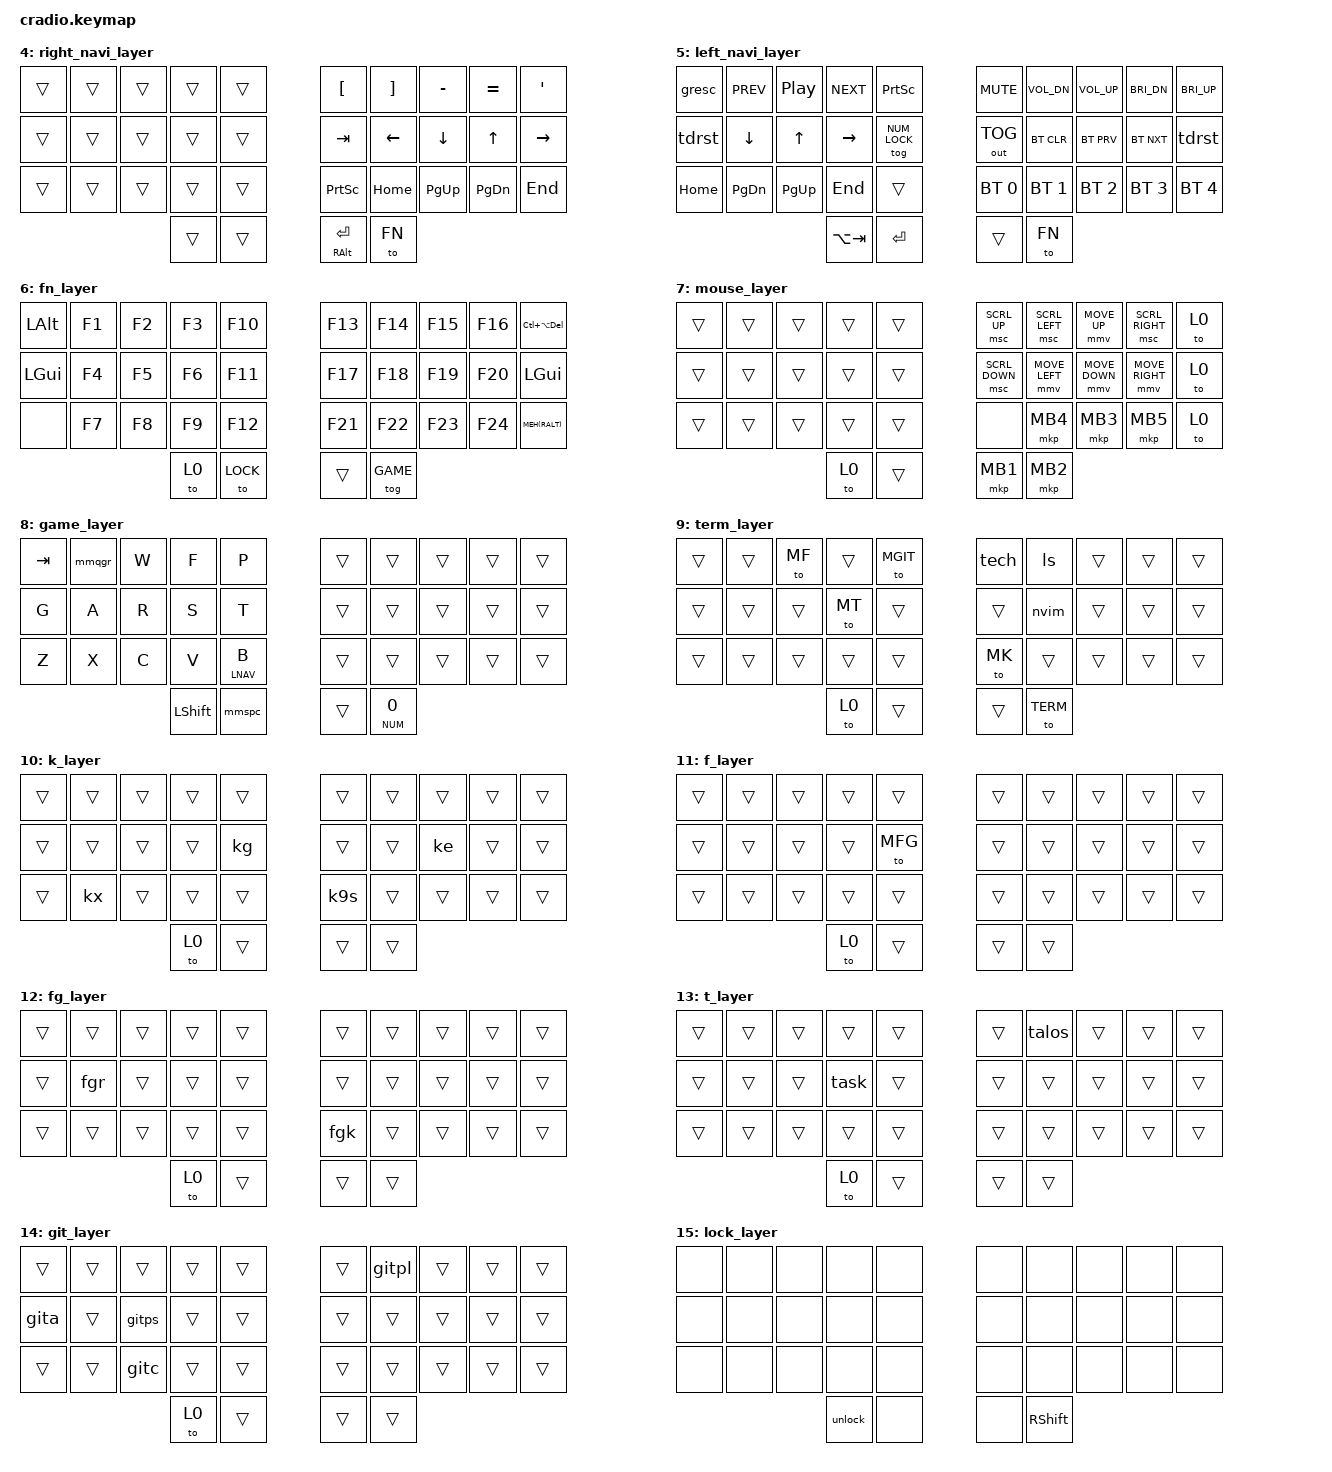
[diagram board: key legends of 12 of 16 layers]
// vi: ft=c
// Copyright (c) 2022 The ZMK Contributors
// SPDX-License-Identifier: MIT

#include <behaviors.dtsi>
// https://github.com/zmkfirmware/zmk/tree/main/app/dts/behaviors
#include <dt-bindings/zmk/keys.h>
#include <dt-bindings/zmk/bt.h>
#include <dt-bindings/zmk/outputs.h>
#include <dt-bindings/zmk/ext_power.h>

// my own code
#include "custom.h"

// timeouts
// current switch timings: stock Akko Crystal Silver on Sweep High
#define CFAST <30>
#define CSLOW <50>

// Layers name to integer definition
#define DEFAULT 0
#define LNUM 1
#define NUM 2
#define NUM_LOCK 3
#define RNAV 4
#define LNAV 5
#define FN 6
#define MOUSE 7
#define GAME 8
#define TERM 9
// macro layers
#define MK 10
#define MF 11
#define MFG 12
#define MT 13
#define MGIT 14
#define LOCK 15

#define EMPTYLAYER \
    &trans  &trans  &trans  &trans  &trans    &trans  &trans  &trans  &trans  &trans \
    &trans  &trans  &trans  &trans  &trans    &trans  &trans  &trans  &trans  &trans \
    &trans  &trans  &trans  &trans  &trans    &trans  &trans  &trans  &trans  &trans \
                            &trans  &trans    &trans  &trans

&sk {
    quick-release;
};
&lt {
    tapping-term-ms = <280>;
    quick-tap-ms = <175>;
    require-prior-idle-ms = <150>;
};
&caps_word {
    continue-list = <BSPC DEL UNDERSCORE MINUS SEMICOLON COLON APOSTROPHE DOUBLE_QUOTES>;
};
// &num_word { // urob fork only
//     layers = <NUM_LOCK>;
//     continue-list = <BSPC DEL DOT AMPERSAND UP DOWN LEFT RIGHT>;
// };

// mouse keys (copied from urob)
#define ZMK_MOUSE_DEFAULT_MOVE_VAL 3750  // 600
#define ZMK_MOUSE_DEFAULT_SCRL_VAL 20    // 10

#include <dt-bindings/zmk/mouse.h>
#include <behaviors/mouse_keys.dtsi>

#include <dt-bindings/zmk/pointing.h>

&mmv {
  acceleration-exponent = <1>;      // 1
  time-to-max-speed-ms = <150>;    // 40
  delay-ms = <0>;                   // 0
};

&msc {
  acceleration-exponent = <2>;      // 0
  time-to-max-speed-ms = <10>;      // 500
  delay-ms = <0>;                   // 10
};

/ {
    behaviors {
        JJ_MM(unlock, unlock, mods = <(MOD_RSFT)>; bindings = <&none>, <&unlockdance>;)
        JJ(unlockdance, unlock_dance, "zmk,behavior-tap-dance", 0, tapping-term-ms = <200>; bindings = <&none>, <&none>, <&to 0>;)
        JJ_TD(tdc, tap_dance_colon, <&kp COLON>, <&kp APOSTROPHE>, <&kp DOUBLE_QUOTES>, <&kp SEMICOLON>)
        JJ_MM(mmsc, mod_morph_semicolon, mods = <(MOD_LSFT)>; bindings = <&tdc>, <&kp SEMICOLON>;)
        JJ_MM(mmsa, mod_morph_semicolon_apostrophe, mods = <(MOD_RALT)>; bindings = <&mmsc>, <&kp DOUBLE_QUOTES>;)
        JJ_MM(mmoe, mod_morph_o_enter, mods = <(MOD_RALT)>; bindings = <&kp O>, <&kp ENTER>;)
        JJ_MM(mmgrave, mod_morph_grave, mods = <(MOD_LSFT)>; bindings = <&kp TILDE>, <&kp GRAVE>;)
        JJ_MM(mmpipe, mod_morph_pipe_backslash, mods = <(MOD_LSFT)>; bindings = <&kp PIPE>, <&kp BSLH>;)
        JJ_MM(mmqgr, mod_morph_q_grave, mods = <(MOD_RALT)>; bindings = <&kp Q>, <&mmgrave>;)
        JJ_MM(mmat, mod_morph_a_tab, mods = <(MOD_RALT|MOD_RGUI)>; keep-mods = <(MOD_RALT|MOD_RGUI)>; bindings = <&kp A>, <&kp TAB>;)
        JJ_MM(mmrr, mod_morph_r_repeat_key, mods = <(MOD_RALT)>; bindings = <&kp R>, <&key_repeat>;)
        JJ_MM(mmts, mod_morph_t_shift, mods = <(MOD_RALT|MOD_LALT)>; bindings = <&kp T>, <&sk LSHFT>;)
        JJ_MM(mmns, mod_morph_n_shift, mods = <(MOD_RALT|MOD_LALT)>; bindings = <&kp N>, <&sk LSHFT>;)
        JJ_MM(mmcaps, mod_morph_caps, mods = <(MOD_LSFT)>; bindings = <&kp ESC>, <&kp CAPSLOCK>;)
        JJ_MM(mmspc, mod_morph_space_caps_word, mods = <(MOD_LSFT)>; bindings = <&kp SPACE>, <&caps_word>;)
        JJ_HT_HOLD(caps, caps_word_hold, bindings = <&kp>, <&mmcaps>;)
        JJ_HT_HOLD(spc, space_stuff, bindings = <&kp>, <&mmspc>;)
        // JJ_HT_HOLD(shft, smart_shift, hold-while-undecided; bindings = <&kp>, <&mmshift>;)
        // JJ_MM(mmshift, mod_morph_shift, mods = <(MOD_LSFT)>; bindings = <&sk LSHFT>, <&caps_word>;)
        // JJ_HT_HOLD(spc, space_shift, bindings = <&kp>, <&kp>;)
        JJ_HT_HOLD(rm, repeat_mod, bindings = <&kp>, <&key_repeat>;)
        JJ_HT_HOLD(mto, mod_tap_to_layer, bindings = <&sk>, <&to>;)
        JJ_HT_HOLD(mtog, mod_tap_toggle_layer, bindings = <&sk>, <&tog>;)
        JJ_HT_HOLD(lt2, layer_tap_2, bindings = <&mo>, <&to>;)
        JJ_MM(mmzd, mod_morph_z_delete, mods = <(MOD_RALT)>; bindings = <&kp Z>, <&kp DEL>;)
        JJ_HT_TAP(ltz, layer_tap_z, bindings = <&mo>, <&mmzd>;)
        JJ_HT_TAP(hm, homerow_mods, bindings = <&kp>, <&kp>;)
        JJ_HML_34(hl, homerow_mods_left, bindings = <&kp>, <&kp>;)
        JJ_HMR_34(hr, homerow_mods_right, bindings = <&kp>, <&kp>;)
        JJ_HT_HOLD(nl, num_layer_stuff, quick-tap-ms = <200>; bindings = <&mo>, <&key_repeat>;)
        // JJ_HT_HOLD(nl, num_layer_stuff, hold-while-undecided; bindings = <&mo>, <&mmnl>;)
        JJ_HT_HOLD(bs, backspace_meh, quick-tap-ms = <200>; bindings = <&kp>, <&kp>;)
        // JJ_MM(mmnl, mod_morph_num_layer_caps_word, mods = <(MOD_LSFT)>; bindings = <&key_repeat>, <&kp CAPSLOCK>;)
        JJ_TD(numdot, num_layer_dot, <&kp DOT>, <&none>, <&kp LC(LA(DEL))>, <&tog GAME>)
        JJ_MM(mmctrlspc, mod_morph_ctrl_space, mods = <(MOD_LSFT)>; bindings = <&kp SPACE>, <&kp LCTRL>;)
        JJ_TD(tdrst, tap_dance_reset, <&sys_reset>, <&none>, <&bootloader>)
    };
    keymap {
        compatible = "zmk,keymap";
        default_layer {
            bindings = <
            //╭──────────┬──────────┬──────────┬──────────┬──────────╮   ╭──────────┬──────────┬──────────┬──────────┬──────────╮
            //│  Q       │  W       │  F       │  P       │  G       │   │  J       │  L       │  U       │  Y       │ :;"'     │
                &mmqgr     &kp W      &kp F      &kp P      &kp G          &kp J      &kp L      &kp U      &kp Y      &mmsa
            //├──────────┼──────────┼──────────┼──────────┼──────────┤   ├──────────┼──────────┼──────────┼──────────┼──────────┤
            //│  A       │  R       │  S       │  T       │  D       │   │  H       │  N       │  E       │  I       │  O       │
                &mmat      &mmrr      &kp S      &mmts     &lt TERM D      &kp H      &mmns      &kp E      &kp I      &kp O
            //├──────────┼──────────┼──────────┼──────────┼──────────┤   ├──────────┼──────────┼──────────┼──────────┼──────────┤
            //│  Z       │  X       │  C       │  V       │  B       │   │  K       │  M       │  ,<      │  .>      │  /?      │
               &ltz FN Z &hl LCTRL X &hl RALT C &hl RGUI V &lt LNAV B     &kp K &hr LGUI M &hr LALT COMMA &hr LCTRL DOT &lt MOUSE FSLH
            //╰──────────┴──────────┴──────────┼──────────┼──────────┤   ├──────────┼──────────┼──────────┴──────────┴──────────╯
                                    &caps LCTRL ESC &spc LSHFT SPACE &bs MEH(RALT) BSPC &nl NUM NUM
            //                                 ╰──────────┴──────────╯   ╰──────────┴──────────╯
            // esc gets thumb cuz vim & as safe key to verify layer 0
	    // mmsa = tap for colon, shift for semicolon, RALT for double quotes, NUM layer for single quotes
            >;
        };
        num_layer {
            bindings = < // TODO: decide whether to split this or not
            //╭──────────┬──────────┬──────────┬──────────┬──────────╮   ╭──────────┬──────────┬──────────┬──────────┬──────────╮
            //│ `~       │  1       │  2       │  3       │  \|      │   │ [{       │ HOME     │ UP       │ END      │ =+       │
                &mmgrave   &kp N1     &kp N2     &kp N3     &kp COMMA      &mmpipe &hm PG_UP HOME &kp UP &hm PG_DN END &kp BSPC
            //├──────────┼──────────┼──────────┼──────────┼──────────┤   ├──────────┼──────────┼──────────┼──────────┼──────────┤
            //│ TAB      │  4       │  5       │  6       │  .       │   │ ]}       │ LEFT     │ DOWN     │ RIGHT    │ '"       │
                &kp ESC    &kp N4     &kp N5     &kp N6     &kp DOT        &kp TAB    &kp LEFT   &kp DOWN   &kp RIGHT  &kp APOS
            //├──────────┼──────────┼──────────┼──────────┼──────────┤   ├──────────┼──────────┼──────────┼──────────┼──────────┤
            //│ DELETE   │  7       │  8       │  9       │  0       │   │ TAB      │ PG_UP    │ -_       │ PG_DN    │ PSCRN    │
                &kp DEL    &kp N7     &kp N8     &kp N9     &kp N0         &kp LBKT   &kp RBKT   &kp MINUS  &kp EQUAL  &kp PSCRN
            //╰──────────┴──────────┴──────────┼──────────┼──────────┤   ├──────────┼──────────┼──────────┴──────────┴──────────╯
                                    &mtog LCTRL NUM_LOCK &spc LSHFT SPACE &bs MEH(RALT) BSPC &none
            //                                 ╰──────────┴──────────╯   ╰──────────┴──────────╯
            >;
        };
        num_hold_layer { bindings = <EMPTYLAYER>; };
        num_lock_layer { bindings = <EMPTYLAYER>; };
        right_navi_layer {
            bindings = <
            //╭──────────┬──────────┬──────────┬──────────┬──────────╮   ╭──────────┬──────────┬──────────┬──────────┬──────────╮
            //│ `~       │  1       │  2       │  3       │  \|      │   │ [{       │ ]}       │ -_       │ =+       │ '"       │
                &trans     &trans     &trans     &trans     &trans         &kp LBKT   &kp RBKT   &kp MINUS  &kp EQUAL  &kp APOS
            //├──────────┼──────────┼──────────┼──────────┼──────────┤   ├──────────┼──────────┼──────────┼──────────┼──────────┤
            //│ TAB      │  4       │  5       │  6       │  0       │   │ TAB      │ LEFT     │ DOWN     │ UP       │ RIGHT    │
                &trans     &trans     &trans     &trans     &trans         &kp TAB    &kp LEFT   &kp DOWN   &kp UP     &kp RIGHT
            //├──────────┼──────────┼──────────┼──────────┼──────────┤   ├──────────┼──────────┼──────────┼──────────┼──────────┤
            //│ DELETE   │  7       │  8       │  9       │  0       │   │ PSCRN    │ HOME     │ PG_UP    │ PG_DN    │ END      │
                &trans     &trans     &trans     &trans     &trans         &kp PSCRN  &kp HOME   &kp PG_UP &kp PG_DN   &kp END
            //╰──────────┴──────────┴──────────┼──────────┼──────────┤   ├──────────┼──────────┼──────────┴──────────┴──────────╯
                                                &trans      &trans        &mt RALT ENTER &to FN
            //                                 ╰──────────┴──────────╯   ╰──────────┴──────────╯
            >;
        };
        left_navi_layer {
            bindings = <
            //╭──────────┬──────────┬──────────┬──────────┬──────────╮   ╭──────────┬──────────┬──────────┬──────────┬──────────╮
            //│ `~ESC    │ PREV SONG│PLAY/PAUSE│ NEXT SONG│ PSCRN    │   │          │          │          │          │          │
                &gresc    &kp C_PREV  &kp C_PP  &kp C_NEXT  &kp PSCRN &kp C_MUTE &kp C_VOL_DN &kp C_VOL_UP &kp C_BRI_DN &kp C_BRI_UP
            //├──────────┼──────────┼──────────┼──────────┼──────────┤   ├──────────┼──────────┼──────────┼──────────┼──────────┤
            //│ LEFT     │ DOWN     │ UP       │ RIGHT    │ Num Layer│   │          │TODO:BTDSC│          │          │          │
                &tdrst   &kp DOWN   &kp UP   &kp RIGHT &tog NUM_LOCK      &out OUT_TOG &bt BT_CLR &bt BT_PRV &bt BT_NXT &tdrst
            //├──────────┼──────────┼──────────┼──────────┼──────────┤   ├──────────┼──────────┼──────────┼──────────┼──────────┤
            //│ HOME     │ PG_DN    │ PG_UP    │ END      │          │   │          │          │          │          │          │
                &kp HOME  &kp PG_DN   &kp PG_UP  &kp END    &trans    &bt BT_SEL 0 &bt BT_SEL 1 &bt BT_SEL 2 &bt BT_SEL 3 &bt BT_SEL 4
            //╰──────────┴──────────┴──────────┼──────────┼──────────┤   ├──────────┼──────────┼──────────┴──────────┴──────────╯
                                                &kp LA(TAB) &kp ENTER      &trans     &to FN
            //                                 ╰──────────┴──────────╯   ╰──────────┴──────────╯
            >;
        };
        fn_layer {
            bindings = <
            //╭──────────┬──────────┬──────────┬──────────┬──────────╮   ╭──────────┬──────────┬──────────┬──────────┬──────────╮
            //│ LALT     │ F1       │ F2       │ F3       │ F10      │   │ F13      │ F14      │ F15      │ F16      │ LALT     │
                &kp LALT   &kp F1     &kp F2     &kp F3     &kp F10        &kp F13    &kp F14    &kp F15    &kp F16 &kp LC(LA(DEL))
            //├──────────┼──────────┼──────────┼──────────┼──────────┤   ├──────────┼──────────┼──────────┼──────────┼──────────┤
            //│ LGUI     │ F4       │ F5       │ F6       │ F11      │   │ F18      │ F19      │ F20      │ F21      │ LGUI     │
                &kp LGUI   &kp F4     &kp F5     &kp F6     &kp F11        &kp F17    &kp F18    &kp F19    &kp F20    &kp LGUI
            //├──────────┼──────────┼──────────┼──────────┼──────────┤   ├──────────┼──────────┼──────────┼──────────┼──────────┤
            //│ NONE     │ F7       │ F8       │ F9       │ F12      │   │ F23      │ F24      │ F23      │ F24      │ MEH      │
                &none      &kp F7     &kp F8     &kp F9     &kp F12        &kp F21    &kp F22    &kp F23    &kp F24 &kp MEH(RALT)
            //╰──────────┴──────────┴──────────┼──────────┼──────────┤   ├──────────┼──────────┼──────────┴──────────┴──────────╯
                                                &to 0       &to LOCK       &trans     &tog GAME
            //                                 ╰──────────┴──────────╯   ╰──────────┴──────────╯
            >;
        };
        mouse_layer {
            bindings = <
            //╭──────────┬──────────┬──────────┬──────────┬──────────╮   ╭──────────┬──────────┬──────────┬──────────┬──────────╮
            //│ `~       │  1       │  2       │  3       │  \|      │   │ [{       │ ]}       │ -_       │ =+       │ '"       │
                &trans     &trans     &trans     &trans     &trans &msc SCRL_UP &msc SCRL_LEFT &mmv MOVE_UP &msc SCRL_RIGHT &to 0
            //├──────────┼──────────┼──────────┼──────────┼──────────┤   ├──────────┼──────────┼──────────┼──────────┼──────────┤
            //│ TAB      │  4       │  5       │  6       │  0       │   │ TAB      │ LEFT     │ DOWN     │ UP       │ RIGHT    │
                &trans     &trans     &trans     &trans     &trans &msc SCRL_DOWN &mmv MOVE_LEFT &mmv MOVE_DOWN &mmv MOVE_RIGHT &to 0
            //├──────────┼──────────┼──────────┼──────────┼──────────┤   ├──────────┼──────────┼──────────┼──────────┼──────────┤
            //│ DELETE   │  7       │  8       │  9       │  0       │   │ PSCRN    │ HOME     │ PG_UP    │ PG_DN    │ END      │
                &trans     &trans     &trans     &trans     &trans         &none      &mkp MB4   &mkp MB3   &mkp MB5   &to 0
            //╰──────────┴──────────┴──────────┼──────────┼──────────┤   ├──────────┼──────────┼──────────┴──────────┴──────────╯
                                                &to 0       &trans         &mkp MB1   &mkp MB2
            //                                 ╰──────────┴──────────╯   ╰──────────┴──────────╯
            >;
        };
        game_layer {
            bindings = <
            // NOTE: This is suited to my gaming habits.
            // I don't ever bind anything to D (QWERTY's G) so that I don't accidentally fat finger T (QWERTY's F) and throw a grenade.
            // I want the row stagger of the middle 3 rows for WASD as the leftmost 3 rows is awkward, 
            // and I want pinky to be used for things other than sprint, thus the shift of the first 2 rows by 1 column to the right.
            //╭──────────┬──────────┬──────────┬──────────┬──────────╮   ╭──────────┬──────────┬──────────┬──────────┬──────────╮
            //│  TAB     │  Q       │  W       │  F       │  P       │   │  J       │  L       │  U       │  Y       │ ;:'"     │
                &kp TAB    &mmqgr     &kp W      &kp F      &kp P          &trans     &trans     &trans     &trans     &trans
            //├──────────┼──────────┼──────────┼──────────┼──────────┤   ├──────────┼──────────┼──────────┼──────────┼──────────┤
            //│  G       │  A       │  R       │  S       │  T       │   │  H       │  N       │  E       │  I       │  O       │
                &kp G      &kp A      &kp R      &kp S      &kp T          &trans     &trans     &trans     &trans     &trans
            //├──────────┼──────────┼──────────┼──────────┼──────────┤   ├──────────┼──────────┼──────────┼──────────┼──────────┤
            //│  Z       │  X       │  C       │  V       │  B       │   │  K       │  M       │  ,<      │  .>      │  /?      │
                &kp Z      &kp X      &kp C      &kp V     &lt LNAV B      &trans     &trans     &trans     &trans     &trans
            //╰──────────┴──────────┴──────────┼──────────┼──────────┤   ├──────────┼──────────┼──────────┴──────────┴──────────╯
                                                &kp LSHFT   &mmspc         &trans    &lt2 NUM 0
            //                                 ╰──────────┴──────────╯   ╰──────────┴──────────╯
            // esc gets thumb cuz vim & as safe key to verify layer 0
            >;
        };
        term_layer {
            bindings = <
            //╭──────────┬──────────┬──────────┬──────────┬──────────╮   ╭──────────┬──────────┬──────────┬──────────┬──────────╮
            //│  Q       │  W       │  F       │  P       │  G       │   │  J       │  L       │  U       │  Y       │ ;:'"     │
                &trans     &trans     &to MF     &trans     &to MGIT       &tech      &ls        &trans     &trans     &trans
            //├──────────┼──────────┼──────────┼──────────┼──────────┤   ├──────────┼──────────┼──────────┼──────────┼──────────┤
            //│  A       │  R       │  S       │  T       │  D       │   │  H       │  N       │  E       │  I       │  O       │
                &trans     &trans     &trans     &to MT     &trans         &trans     &nvim      &trans     &trans     &trans
            //├──────────┼──────────┼──────────┼──────────┼──────────┤   ├──────────┼──────────┼──────────┼──────────┼──────────┤
            //│  Z       │  X       │  C       │  V       │  B       │   │  K       │  M       │  ,<      │  .>      │  /?      │
                &trans     &trans     &trans     &trans     &trans         &to MK     &trans     &trans     &trans     &trans
            //╰──────────┴──────────┴──────────┼──────────┼──────────┤   ├──────────┼──────────┼──────────┴──────────┴──────────╯
                                                &to 0       &trans         &trans     &to TERM
            //                                 ╰──────────┴──────────╯   ╰──────────┴──────────╯
            >;
        };
        k_layer {
            bindings = <
            //╭──────────┬──────────┬──────────┬──────────┬──────────╮   ╭──────────┬──────────┬──────────┬──────────┬──────────╮
            //│  Q       │  W       │  F       │  P       │  B       │   │  J       │  L       │  U       │  Y       │ '"       │
                &trans     &trans     &trans     &trans     &trans         &trans     &trans     &trans     &trans     &trans
            //├──────────┼──────────┼──────────┼──────────┼──────────┤   ├──────────┼──────────┼──────────┼──────────┼──────────┤
            //│  A       │  R       │  S       │  T       │  G       │   │  M       │  N       │  E       │  I       │  O       │
                &trans     &trans     &trans     &trans     &kg            &trans     &trans     &ke        &trans     &trans
            //├──────────┼──────────┼──────────┼──────────┼──────────┤   ├──────────┼──────────┼──────────┼──────────┼──────────┤
            //│  Z       │  X       │  C       │  D       │  V       │   │  K       │  H       │  ,<      │  .>      │  /?      │
                &trans     &kx        &trans     &trans     &trans         &k9s       &trans     &trans     &trans     &trans
            //╰──────────┴──────────┴──────────┼──────────┼──────────┤   ├──────────┼──────────┼──────────┴──────────┴──────────╯
                                                &to 0       &trans         &trans     &trans
            //                                 ╰──────────┴──────────╯   ╰──────────┴──────────╯
            >;
        };
        f_layer {
            bindings = <
            //╭──────────┬──────────┬──────────┬──────────┬──────────╮   ╭──────────┬──────────┬──────────┬──────────┬──────────╮
            //│  Q       │  W       │  F       │  P       │  B       │   │  J       │  L       │  U       │  Y       │ '"       │
                &trans     &trans     &trans     &trans     &trans         &trans     &trans     &trans     &trans     &trans
            //├──────────┼──────────┼──────────┼──────────┼──────────┤   ├──────────┼──────────┼──────────┼──────────┼──────────┤
            //│  A       │  R       │  S       │  T       │  G       │   │  M       │  N       │  E       │  I       │  O       │
                &trans     &trans     &trans     &trans     &to MFG        &trans     &trans     &trans     &trans     &trans
            //├──────────┼──────────┼──────────┼──────────┼──────────┤   ├──────────┼──────────┼──────────┼──────────┼──────────┤
            //│  Z       │  X       │  C       │  D       │  V       │   │  K       │  H       │  ,<      │  .>      │  /?      │
                &trans     &trans     &trans     &trans     &trans         &trans     &trans     &trans     &trans     &trans
            //╰──────────┴──────────┴──────────┼──────────┼──────────┤   ├──────────┼──────────┼──────────┴──────────┴──────────╯
                                                &to 0       &trans         &trans     &trans
            //                                 ╰──────────┴──────────╯   ╰──────────┴──────────╯
            >;
        };
        fg_layer {
            bindings = <
            //╭──────────┬──────────┬──────────┬──────────┬──────────╮   ╭──────────┬──────────┬──────────┬──────────┬──────────╮
            //│  Q       │  W       │  F       │  P       │  B       │   │  J       │  L       │  U       │  Y       │ '"       │
                &trans     &trans     &trans     &trans     &trans         &trans     &trans     &trans     &trans     &trans
            //├──────────┼──────────┼──────────┼──────────┼──────────┤   ├──────────┼──────────┼──────────┼──────────┼──────────┤
            //│  A       │  R       │  S       │  T       │  G       │   │  M       │  N       │  E       │  I       │  O       │
                &trans     &fgr       &trans     &trans     &trans         &trans     &trans     &trans     &trans     &trans
            //├──────────┼──────────┼──────────┼──────────┼──────────┤   ├──────────┼──────────┼──────────┼──────────┼──────────┤
            //│  Z       │  X       │  C       │  D       │  V       │   │  K       │  H       │  ,<      │  .>      │  /?      │
                &trans     &trans     &trans     &trans     &trans         &fgk       &trans     &trans     &trans     &trans
            //╰──────────┴──────────┴──────────┼──────────┼──────────┤   ├──────────┼──────────┼──────────┴──────────┴──────────╯
                                                &to 0       &trans         &trans     &trans
            //                                 ╰──────────┴──────────╯   ╰──────────┴──────────╯
            >;
        };
        t_layer {
            bindings = <
            //╭──────────┬──────────┬──────────┬──────────┬──────────╮   ╭──────────┬──────────┬──────────┬──────────┬──────────╮
            //│  Q       │  W       │  F       │  P       │  B       │   │  J       │  L       │  U       │  Y       │ '"       │
                &trans     &trans     &trans     &trans     &trans         &trans     &talos     &trans     &trans     &trans
            //├──────────┼──────────┼──────────┼──────────┼──────────┤   ├──────────┼──────────┼──────────┼──────────┼──────────┤
            //│  A       │  R       │  S       │  T       │  G       │   │  M       │  N       │  E       │  I       │  O       │
                &trans     &trans     &trans     &task      &trans         &trans     &trans     &trans     &trans     &trans
            //├──────────┼──────────┼──────────┼──────────┼──────────┤   ├──────────┼──────────┼──────────┼──────────┼──────────┤
            //│  Z       │  X       │  C       │  D       │  V       │   │  K       │  H       │  ,<      │  .>      │  /?      │
                &trans     &trans     &trans     &trans     &trans         &trans     &trans     &trans     &trans     &trans
            //╰──────────┴──────────┴──────────┼──────────┼──────────┤   ├──────────┼──────────┼──────────┴──────────┴──────────╯
                                                &to 0       &trans         &trans     &trans
            //                                 ╰──────────┴──────────╯   ╰──────────┴──────────╯
            >;
        };
        git_layer {
            bindings = <
            //╭──────────┬──────────┬──────────┬──────────┬──────────╮   ╭──────────┬──────────┬──────────┬──────────┬──────────╮
            //│  Q       │  W       │  F       │  P       │  G       │   │  J       │  L       │  U       │  Y       │ ;:'"     │
                &trans     &trans     &trans     &trans     &trans         &trans     &gitpl     &trans     &trans     &trans
            //├──────────┼──────────┼──────────┼──────────┼──────────┤   ├──────────┼──────────┼──────────┼──────────┼──────────┤
            //│  A       │  R       │  S       │  T       │  D       │   │  H       │  N       │  E       │  I       │  O       │
                &gita      &trans     &gitps     &trans     &trans         &trans     &trans     &trans     &trans     &trans
            //├──────────┼──────────┼──────────┼──────────┼──────────┤   ├──────────┼──────────┼──────────┼──────────┼──────────┤
            //│  Z       │  X       │  C       │  V       │  B       │   │  K       │  M       │  ,<      │  .>      │  /?      │
                &trans     &trans     &gitc      &trans     &trans         &trans     &trans     &trans     &trans     &trans
            //╰──────────┴──────────┴──────────┼──────────┼──────────┤   ├──────────┼──────────┼──────────┴──────────┴──────────╯
                                                &to 0       &trans         &trans     &trans
            //                                 ╰──────────┴──────────╯   ╰──────────┴──────────╯
            >;
        };
        lock_layer {
            bindings = <
                &none &none &none &none &none  &none &none &none &none &none
                &none &none &none &none &none  &none &none &none &none &none
                &none &none &none &none &none  &none &none &none &none &none
                                &unlock &none  &none &kp RSHFT
            >;
        };
	// TODO: mouse layer
    };
    macros {
        ZMK_MACRO(smart_shift, bindings = <&macro_release &caps_word>, <&sk LSHFT>;)
        ZMK_MACRO(nvim, bindings = <&kp N &kp V &kp I &kp M &kp SPACE &to 0>;)
        ZMK_MACRO(ls, bindings = <&kp L &kp S &kp SPACE &kp KP_MINUS>, <&macro_press &kp LSHFT>, <&kp A>, <&macro_release &kp LSHFT>, <&kp L &kp H &kp SPACE &to 0>;)
        ZMK_MACRO(task, bindings = <&kp T &kp A &kp S &kp K &kp SPACE &to 0>;)
        ZMK_MACRO(talos, bindings = <&kp T &kp A &kp L &kp O &kp S &kp C &kp T &kp L &kp SPACE &to 0>;) // talosctl
        ZMK_MACRO(tech, bindings = <&kp J &kp J &kp G &kp A &kp D &kp G &kp E &kp T &kp S &kp DOT &kp T &kp E &kp C &kp H &to 0>;) // jjgadgets.tech
        ZMK_MACRO(gita, bindings = <&kp G &kp I &kp T &kp SPACE &kp A &kp D &kp D &kp SPACE &to 0>;) // git add
        ZMK_MACRO(gitc, bindings = <&kp G &kp I &kp T &kp SPACE &kp C &kp O &kp M &kp M &kp I &kp T &kp SPACE &kp KP_MINUS &kp KP_MINUS &kp G &kp P &kp G &kp KP_MINUS &kp S &kp I &kp G &kp N &kp SPACE &kp KP_MINUS &kp M &kp SPACE &kp DOUBLE_QUOTES &kp DOUBLE_QUOTES &kp LEFT &kp SPACE &to 0>;) // git add
        ZMK_MACRO(gitps, bindings = <&kp G &kp I &kp T &kp SPACE &kp P &kp U &kp S &kp H &to 0>;)
        ZMK_MACRO(gitpl, bindings = <&kp G &kp I &kp T &kp SPACE &kp P &kp U &kp L &kp L &to 0>;)
        ZMK_MACRO(fgr, bindings = <&kp F &kp L &kp U &kp X &kp SPACE &kp G &kp E &kp T &kp SPACE &kp H &kp R &kp SPACE &kp KP_MINUS &kp N &kp SPACE &to 0>;) // flux get hr
        ZMK_MACRO(fgk, bindings = <&kp F &kp L &kp U &kp X &kp SPACE &kp G &kp E &kp T &kp SPACE &kp K &kp S &kp SPACE &to 0>;) // flux get ks
        ZMK_MACRO(k9s, bindings = <&kp K &kp N9 &kp S &kp ENTER &to 0>;)
        ZMK_MACRO(kg, bindings = <&kp K &kp U &kp B &kp E &kp C &kp T &kp L &kp SPACE &kp G &kp E &kp T &kp SPACE &kp KP_MINUS &kp N &kp SPACE &kp LEFT &kp LEFT &kp LEFT &kp LEFT &kp SPACE &to 0>;) // kubectl get -n
        ZMK_MACRO(ke, bindings = <&kp K &kp U &kp B &kp E &kp C &kp T &kp L &kp SPACE &kp E &kp D &kp I &kp T &kp SPACE &kp KP_MINUS &kp N &kp SPACE &kp LEFT &kp LEFT &kp LEFT &kp LEFT &kp SPACE &to 0>;) // kubectl edit -n
        ZMK_MACRO(kx, bindings = <&kp K &kp U &kp B &kp E &kp C &kp T &kp L &kp SPACE &kp E &kp X &kp E &kp C &kp SPACE &kp KP_MINUS &kp I &kp T &kp SPACE &kp KP_MINUS &kp N &kp SPACE &kp KP_MINUS &kp KP_MINUS &kp SPACE &kp B &kp A &kp S &kp H &kp LEFT &kp LEFT &kp LEFT &kp LEFT &kp LEFT &kp LEFT &kp LEFT &kp LEFT &kp SPACE &to 0>;) // kubectl exec -it -n
    };
    combos {
        compatible = "zmk,combos";
        game_ctrl {
            timeout-ms = CSLOW;
            key-positions = <31 10>; // left outer thumb + A (default) or G (gaming)
            bindings = <&kp LCTRL>;
            layers = <GAME>;
        };
        game_ctrl2 {
            timeout-ms = CSLOW;
            key-positions = <30 10>; // left outer thumb + A (default) or G (gaming)
            bindings = <&kp LCTRL>;
            layers = <GAME>;
        };
        game_d {
            timeout-ms = CSLOW;
            key-positions = <31 14>; // left outer thumb + D (default) or T (gaming)
            bindings = <&kp D>;
            layers = <GAME>;
        };
        game_d2 {
            timeout-ms = CSLOW;
            key-positions = <30 14>; // left outer thumb + D (default) or T (gaming)
            bindings = <&kp D>;
            layers = <GAME>;
        };
        game_space_hold {
            timeout-ms = CSLOW;
            key-positions = <31 32>; // left outer thumb + D (default) or T (gaming)
            bindings = <&kt SPACE>;
            layers = <GAME>;
        };
        game_esc {
            timeout-ms = CFAST;
            key-positions = <0 1>; // Q + W
            bindings = <&kp ESC>;
            layers = <GAME>;
            require-prior-idle-ms = <JJ_COMBO_IDLE>;
        };
        combo_mouse_layer {
            timeout-ms = CSLOW;
            key-positions = <6 7 8>; // L U Y
            bindings = <&tog MOUSE>;
            layers = <0 LNUM MOUSE GAME>;
            require-prior-idle-ms = <JJ_COMBO_IDLE>;
        };
        combo_grave {
            timeout-ms = CFAST;
            key-positions = <0 1>; // Q + W
            bindings = <&mmgrave>;
            layers = <0>;
            require-prior-idle-ms = <JJ_COMBO_IDLE>;
        };
        combo_tab {
            timeout-ms = CSLOW;
            key-positions = <11 12 13>; // R + S + T
            bindings = <&kp TAB>;
            layers = <0 LNUM NUM_LOCK>;
            require-prior-idle-ms = <JJ_COMBO_IDLE>;
        };
        combo_delete {
            timeout-ms = CFAST;
            key-positions = <20 21>; // Z + X
            bindings = <&kp DEL>;
            layers = <0>;
            require-prior-idle-ms = <JJ_COMBO_IDLE>;
        };
        combo_enter {
            timeout-ms = CSLOW;
            key-positions = <16 17 18>; // N + E + I
            bindings = <&kp ENTER>;
            require-prior-idle-ms = <JJ_COMBO_IDLE>;
        };
        combo_double_quotes {
            timeout-ms = CFAST;
            key-positions = <8 9>; // Y + :
            bindings = <&kp DOUBLE_QUOTES>;
            layers = <0>;
            require-prior-idle-ms = <JJ_COMBO_IDLE>;
        };
        combo_semicolon {
            timeout-ms = CFAST;
            key-positions = <9 19>; // O + :
            bindings = <&kp SEMICOLON>;
            layers = <0>;
            require-prior-idle-ms = <JJ_COMBO_IDLE>;
        };
        combo_left {
            timeout-ms = CSLOW;
            key-positions = <33 16>; // right outer thumb + O key
            bindings = <&kp LEFT>;
            layers = <0>;
        };
        combo_down {
            timeout-ms = CSLOW;
            key-positions = <33 17>; // right outer thumb + O key
            bindings = <&kp DOWN>;
            layers = <0>;
        };
        combo_up {
            timeout-ms = CSLOW;
            key-positions = <33 7>; // right outer thumb + O key
            bindings = <&kp UP>;
            layers = <0>;
        };
        combo_right {
            timeout-ms = CSLOW;
            key-positions = <33 18>; // right outer thumb + O key
            bindings = <&kp RIGHT>;
            layers = <0>;
        };
        combo_apos {
            timeout-ms = CSLOW;
            key-positions = <33 19>; // right outer thumb + O key
            bindings = <&kp APOS>;
            layers = <0>;
        };
        combo_hyphen {
            timeout-ms = CSLOW;
            key-positions = <33 27>; // right outer thumb + O key
            bindings = <&kp MINUS>;
            layers = <0>;
        };
        combo_equal {
            timeout-ms = CSLOW;
            key-positions = <33 28>; // right outer thumb + O key
            bindings = <&kp EQUAL>;
            layers = <0>;
        };
        combo_exclamation {
            timeout-ms = CFAST;
            key-positions = <1 2>; // W + F
            bindings = <&kp EXCLAMATION>;
            layers = <0>;
            require-prior-idle-ms = <JJ_COMBO_IDLE>;
        };
        combo_at {
            timeout-ms = CFAST;
            key-positions = <2 3>; // F + P
            bindings = <&kp AT_SIGN>;
            layers = <0>;
            require-prior-idle-ms = <JJ_COMBO_IDLE>;
        };
        combo_hash {
            timeout-ms = CFAST;
            key-positions = <3 4>; // F + P
            bindings = <&kp HASH>;
            layers = <0>;
            require-prior-idle-ms = <JJ_COMBO_IDLE>;
        };
        combo_dollar {
            timeout-ms = CFAST;
            key-positions = <11 12>; // R + S
            bindings = <&kp DOLLAR>;
            layers = <0>;
            require-prior-idle-ms = <JJ_COMBO_IDLE>;
        };
        combo_percent {
            timeout-ms = CFAST;
            key-positions = <12 13>; // S + T
            bindings = <&kp PERCENT>;
            layers = <0>;
            require-prior-idle-ms = <JJ_COMBO_IDLE>;
        };
        combo_caret {
            timeout-ms = CFAST;
            key-positions = <13 14>; // T + D
            bindings = <&kp CARET>;
            layers = <0>;
            require-prior-idle-ms = <JJ_COMBO_IDLE>;
        };
        combo_ampersand {
            timeout-ms = CFAST;
            key-positions = <21 22>; // X + C
            bindings = <&kp AMPERSAND>;
            layers = <0>;
            require-prior-idle-ms = <JJ_COMBO_IDLE>;
        };
        combo_star {
            timeout-ms = CFAST;
            key-positions = <21 23>; // X + V
            bindings = <&kp STAR>;
            layers = <0>;
            require-prior-idle-ms = <JJ_COMBO_IDLE>;
        };
        combo_left_bracket {
            timeout-ms = CFAST;
            key-positions = <22 23>; // C + V
            bindings = <&kp LEFT_PARENTHESIS>;
            layers = <0>;
            require-prior-idle-ms = <JJ_COMBO_IDLE>;
        };
        combo_right_bracket {
            timeout-ms = CFAST;
            key-positions = <23 24>; // V + B
            bindings = <&kp RIGHT_PARENTHESIS>;
            layers = <0>;
            require-prior-idle-ms = <JJ_COMBO_IDLE>;
        };
        combo_pipe {
            timeout-ms = CFAST;
            key-positions = <5 6>; // J + L
            bindings = <&kp PIPE>;
            layers = <0>;
            require-prior-idle-ms = <JJ_COMBO_IDLE>;
        };
    };
    conditional_layers {
        compatible = "zmk,conditional-layers";
        // layer lock
        num_hold_left {
            if-layers = <NUM>;
            then-layer = <LNUM>;
        };
        //num_hold_right {
        //    if-layers = <NUM>;
        //    then-layer = <RNAV>;
        //};
        num_lock {
            if-layers = <NUM_LOCK>;
            then-layer = <LNUM>;
        };
    };
};

&kscan0 {
    // eager debouncing
    debounce-press-ms = <2>; // increased from 0 to 1 due to G key being wonky af
    debounce-release-ms = <6>; // decreased from 6 to 5 due to G key being wonky af and scan period being reset to 1
    // increasing scan period, *might* reduce power use...?
    // TODO: set press to 0 and scan to 3, verify power
    debounce-scan-period-ms = <2>;
};
